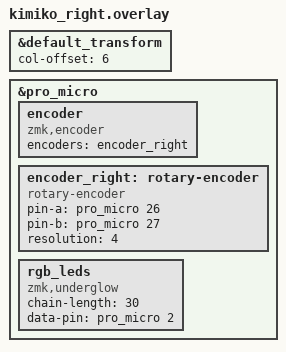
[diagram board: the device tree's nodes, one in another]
// This file was generated from a template. Edit it to match your keyboard.
// See https://zmk.dev/docs/development/hardware-integration/new-shield for more
// instructions.
#include "kimiko.dtsi"

&default_transform {
    col-offset = <6>;
};

&pro_micro {
    encoder: encoder {
        compatible = "zmk,encoder";
        encoders = <&encoder_right>;
    };

    encoder_right: rotary-encoder {
        compatible = "rotary-encoder";
        pin-a = <&pro_micro 26>; // F4
        pin-b = <&pro_micro 27>; // F5
        resolution = <4>;
    };

    rgb_leds: rgb_leds {
        compatible = "zmk,underglow";
        chain-length = <30>;
        data-pin = <&pro_micro 2>; // D3
    };
};

